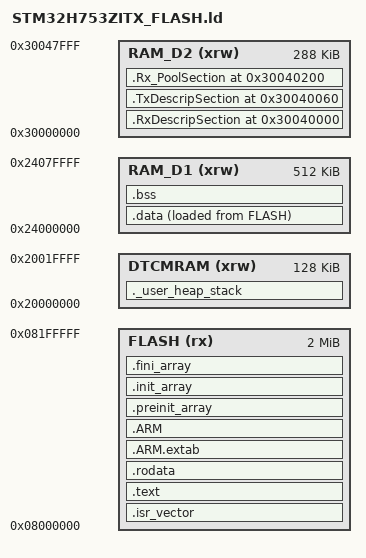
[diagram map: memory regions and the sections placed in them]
ENTRY(Reset_Handler)

MEMORY
{
  FLASH  (rx)  : ORIGIN = 0x08000000, LENGTH = 2048K
  RAM_D1 (xrw) : ORIGIN = 0x24000000, LENGTH = 512K
  RAM_D2 (xrw) : ORIGIN = 0x30000000, LENGTH = 288K
  DTCMRAM (xrw): ORIGIN = 0x20000000, LENGTH = 128K
}

_estack = ORIGIN(DTCMRAM) + LENGTH(DTCMRAM);
_Min_Heap_Size = 0x800;
_Min_Stack_Size = 0x1000;

SECTIONS
{
  .isr_vector : { . = ALIGN(4); KEEP(*(.isr_vector)) . = ALIGN(4); } >FLASH
  .text :
  {
    . = ALIGN(4);
    *(.text) *(.text*) *(.glue_7) *(.glue_7t) *(.eh_frame)
    KEEP(*(.init)) KEEP(*(.fini))
    . = ALIGN(4); _etext = .;
  } >FLASH
  .rodata : { . = ALIGN(4); *(.rodata) *(.rodata*) . = ALIGN(4); } >FLASH
  .ARM.extab : { *(.ARM.extab* .gnu.linkonce.armextab.*) } >FLASH
  .ARM :
  {
    __exidx_start = .;
    *(.ARM.exidx*)
    __exidx_end = .;
  } >FLASH
  .preinit_array :
  {
    PROVIDE_HIDDEN(__preinit_array_start = .);
    KEEP(*(.preinit_array*))
    PROVIDE_HIDDEN(__preinit_array_end = .);
  } >FLASH
  .init_array :
  {
    PROVIDE_HIDDEN(__init_array_start = .);
    KEEP(*(SORT(.init_array.*))) KEEP(*(.init_array*))
    PROVIDE_HIDDEN(__init_array_end = .);
  } >FLASH
  .fini_array :
  {
    PROVIDE_HIDDEN(__fini_array_start = .);
    KEEP(*(SORT(.fini_array.*))) KEEP(*(.fini_array*))
    PROVIDE_HIDDEN(__fini_array_end = .);
  } >FLASH

  _sidata = LOADADDR(.data);
  .data :
  {
    . = ALIGN(4); _sdata = .;
    *(.data) *(.data*)
    . = ALIGN(4); _edata = .;
  } >RAM_D1 AT>FLASH
  .bss :
  {
    . = ALIGN(4); _sbss = .; __bss_start__ = _sbss;
    *(.bss) *(.bss*) *(COMMON)
    . = ALIGN(4); _ebss = .; __bss_end__ = _ebss;
  } >RAM_D1
  ._user_heap_stack :
  {
    . = ALIGN(8); PROVIDE(end = .); PROVIDE(_end = .);
    . = . + _Min_Heap_Size + _Min_Stack_Size;
    . = ALIGN(8);
  } >DTCMRAM

  .RxDescripSection 0x30040000 (NOLOAD) : { KEEP(*(.RxDescripSection)) } >RAM_D2
  .TxDescripSection 0x30040060 (NOLOAD) : { KEEP(*(.TxDescripSection)) } >RAM_D2
  .Rx_PoolSection 0x30040200 (NOLOAD) : { KEEP(*(.Rx_PoolSection)) } >RAM_D2

  .ARM.attributes 0 : { *(.ARM.attributes) }
}
